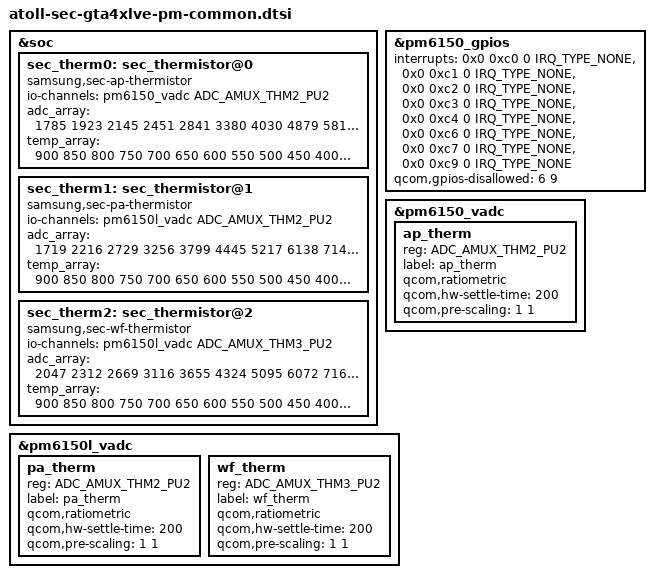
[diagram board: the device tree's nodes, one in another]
/* Copyright (c) 2020, The Linux Foundation. All rights reserved.
 *
 * This program is free software; you can redistribute it and/or modify
 * it under the terms of the GNU General Public License version 2 and
 * only version 2 as published by the Free Software Foundation.
 *
 * This program is distributed in the hope that it will be useful,
 * but WITHOUT ANY WARRANTY; without even the implied warranty of
 * MERCHANTABILITY or FITNESS FOR A PARTICULAR PURPOSE.  See the
 * GNU General Public License for more details.
 */

#include "../atoll-sec-pm-common.dtsi"

&soc {
	/* AP Thermistor table */
	sec_therm0: sec_thermistor@0 {
		compatible = "samsung,sec-ap-thermistor";
		status = "okay";
		io-channels = <&pm6150_vadc ADC_AMUX_THM2_PU2>;
		io-channel-names = "ap_therm";
		adc_array = <1785 1923 2145 2451 2841 3380 4030
			4879 5814 6855 8022 9116 10614 12041 13598 15104
			16971 18701 20133 21575 22752 23812 24872>;
		temp_array = <900 850 800 750 700 650 600
			550 500 450 400 350 300 250 200 150
			100 50 0 (-50) (-100) (-150) (-200)>;
	};

	/* PA Thermistor table */
	sec_therm1: sec_thermistor@1 {
		compatible = "samsung,sec-pa-thermistor";
		status = "okay";
		io-channels = <&pm6150l_vadc ADC_AMUX_THM2_PU2>;
		io-channel-names = "pa_therm";
		adc_array = <1719 2216 2729 3256 3799 4445 5217
			6138 7146 8380 9700 11077 12732 14332 16011 17718
			19385 20995 22391 23617 24784 25716 26413>;
		temp_array = <900 850 800 750 700 650 600
			550 500 450 400 350 300 250 200 150
			100 50 0 (-50) (-100) (-150) (-200)>;
	};

	/* WiFi Thermistor table */
	sec_therm2: sec_thermistor@2 {
		compatible = "samsung,sec-wf-thermistor";
		status = "okay";
		io-channels = <&pm6150l_vadc ADC_AMUX_THM3_PU2>;
		io-channel-names = "wf_therm";
		adc_array = <2047 2312 2669 3116 3655 4324 5095
			6072 7160 8293 9588 10894 12452 14035 15499 17331
			19062 20601 22047 23232 24303 25099 25895>;
		temp_array = <900 850 800 750 700 650 600
			550 500 450 400 350 300 250 200 150
			100 50 0 (-50) (-100) (-150) (-200)>;
	};
};

&pm6150_gpios {
	interrupts = <0x0 0xc0 0 IRQ_TYPE_NONE>,
		<0x0 0xc1 0 IRQ_TYPE_NONE>,
		<0x0 0xc2 0 IRQ_TYPE_NONE>,
		<0x0 0xc3 0 IRQ_TYPE_NONE>,
		<0x0 0xc4 0 IRQ_TYPE_NONE>,
		<0x0 0xc6 0 IRQ_TYPE_NONE>,
		<0x0 0xc7 0 IRQ_TYPE_NONE>,
		<0x0 0xc9 0 IRQ_TYPE_NONE>;
	interrupt-names = "pm6150_gpio1", "pm6150_gpio2",
		"pm6150_gpio3", "pm6150_gpio4", "pm6150_gpio5",
		"pm6150_gpio7", "pm6150_gpio8",
		"pm6150_gpio10";
	qcom,gpios-disallowed = <6 9>;
};

&pm6150_vadc {
	ap_therm: ap_therm {
		reg = <ADC_AMUX_THM2_PU2>;
		label = "ap_therm";
		qcom,ratiometric;
		qcom,hw-settle-time = <200>;
		qcom,pre-scaling = <1 1>;
	};
};

&pm6150l_vadc {
	/delete-node/ pa_therm0;

	pa_therm: pa_therm {
		reg = <ADC_AMUX_THM2_PU2>;
		label = "pa_therm";
		qcom,ratiometric;
		qcom,hw-settle-time = <200>;
		qcom,pre-scaling = <1 1>;
	};

	wf_therm: wf_therm {
		reg = <ADC_AMUX_THM3_PU2>;
		label = "wf_therm";
		qcom,ratiometric;
		qcom,hw-settle-time = <200>;
		qcom,pre-scaling = <1 1>;
	};
};
